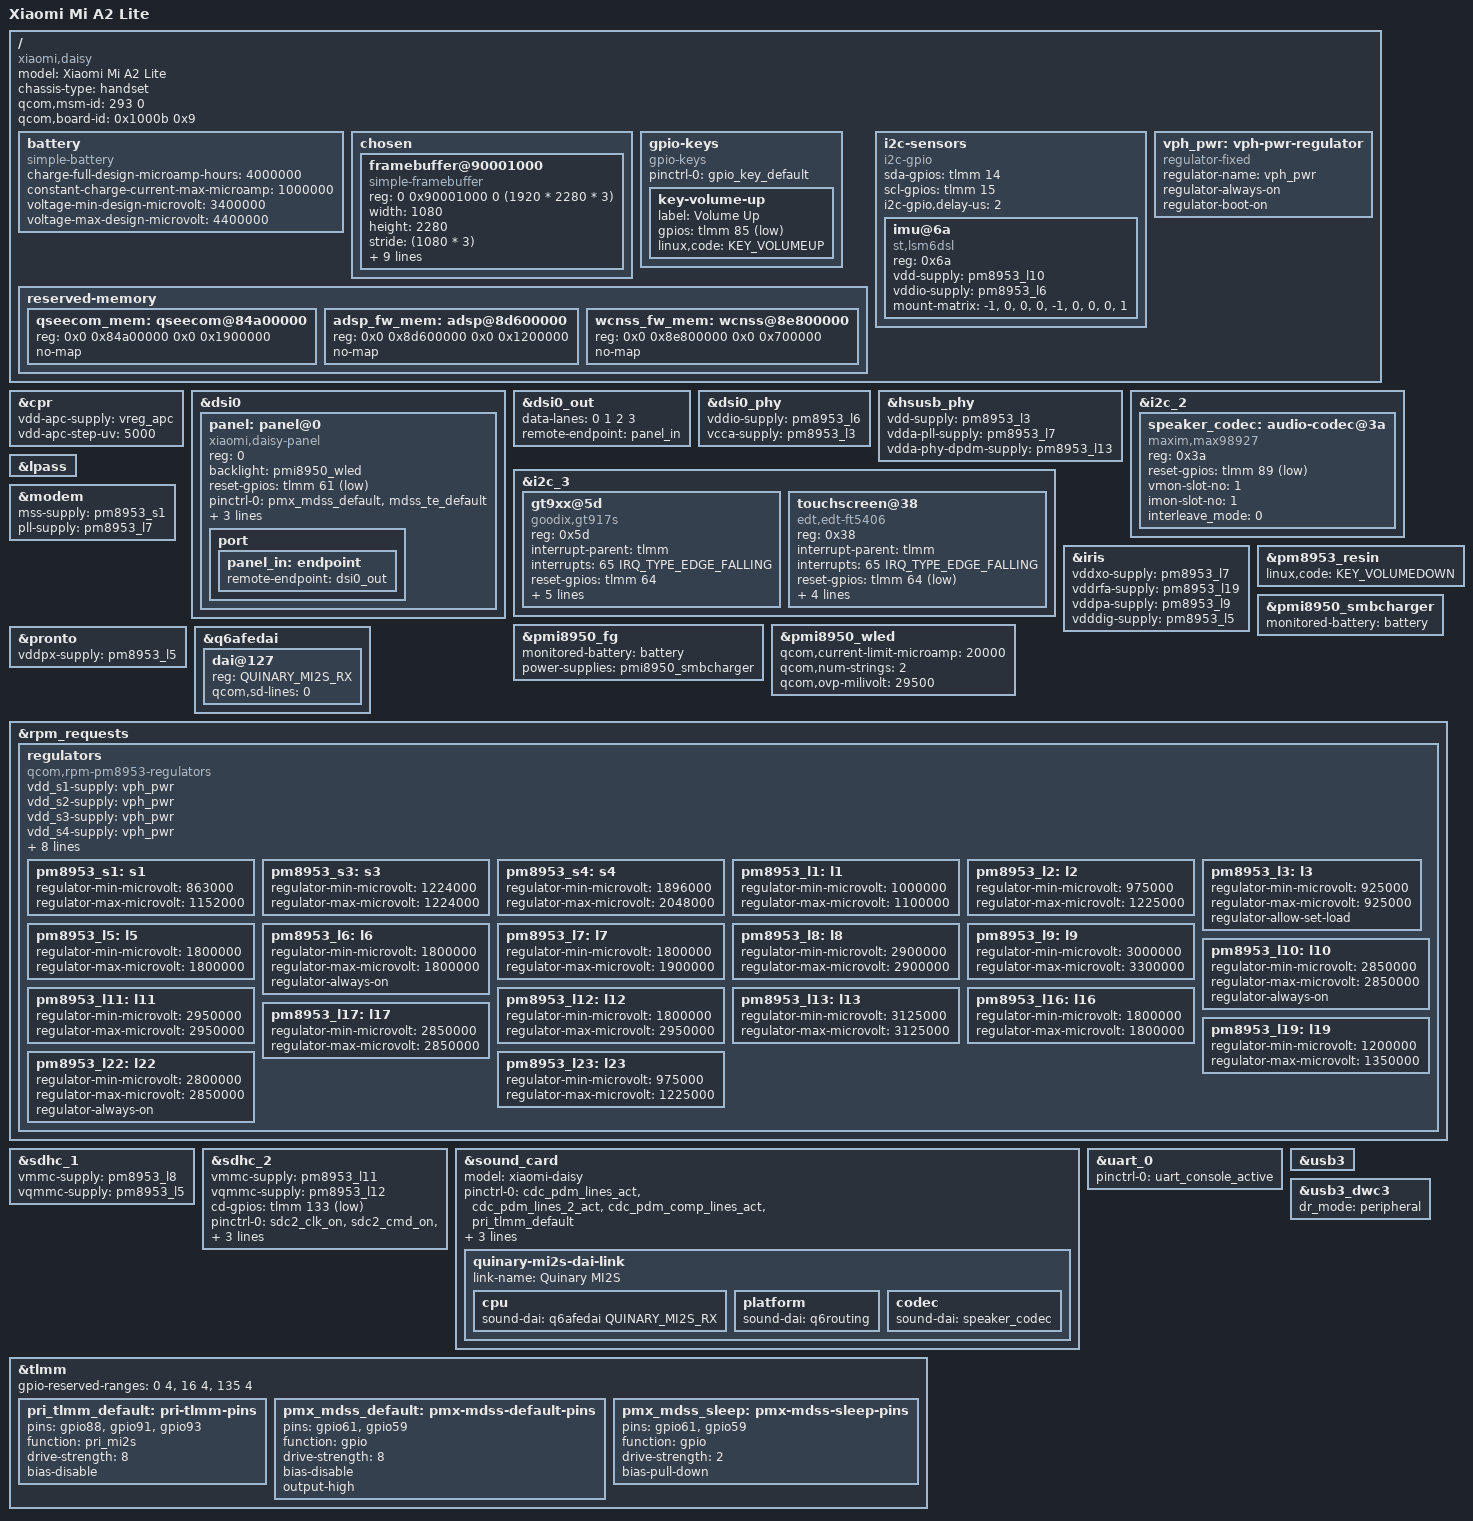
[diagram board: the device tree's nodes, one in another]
// SPDX-License-Identifier: BSD-3-Clause
/*
 * Copyright (c) 2022, Alejandro Tafalla
 */
/dts-v1/;

#include "msm8953.dtsi"
#include "pm8953.dtsi"
#include "pmi8950.dtsi"

#include <dt-bindings/gpio/gpio.h>
#include <dt-bindings/leds/common.h>

/delete-node/ &adsp_fw_mem;
/delete-node/ &qseecom_mem;
/delete-node/ &wcnss_fw_mem;

/ {
	model = "Xiaomi Mi A2 Lite";
	compatible = "xiaomi,daisy", "qcom,msm8953";
	chassis-type = "handset";
	qcom,msm-id = <293 0>;
	qcom,board-id= <0x1000b 0x9>;

	battery: battery {
		compatible = "simple-battery";
		charge-full-design-microamp-hours = <4000000>;
		constant-charge-current-max-microamp = <1000000>;
		voltage-min-design-microvolt = <3400000>;
		voltage-max-design-microvolt = <4400000>;
	};

	chosen {
		#address-cells = <2>;
		#size-cells = <2>;
		ranges;

		framebuffer@90001000 {
			compatible = "simple-framebuffer";
			reg = <0 0x90001000 0 (1920 * 2280 * 3)>;

			width = <1080>;
			height = <2280>;
			stride = <(1080 * 3)>;
			format = "r8g8b8";

			power-domains = <&gcc MDSS_GDSC>;

			clocks = <&gcc GCC_MDSS_AHB_CLK>,
				 <&gcc GCC_MDSS_AXI_CLK>,
				 <&gcc GCC_MDSS_VSYNC_CLK>,
				 <&gcc GCC_MDSS_MDP_CLK>,
				 <&gcc GCC_MDSS_BYTE0_CLK>,
				 <&gcc GCC_MDSS_PCLK0_CLK>,
				 <&gcc GCC_MDSS_ESC0_CLK>;
		};
	};

	gpio-keys {
		compatible = "gpio-keys";

		pinctrl-names = "default";
		pinctrl-0 = <&gpio_key_default>;

		key-volume-up {
			label = "Volume Up";
			gpios = <&tlmm 85 GPIO_ACTIVE_LOW>;
			linux,code = <KEY_VOLUMEUP>;
		};
	};

	reserved-memory {
		qseecom_mem: qseecom@84a00000 {
			reg = <0x0 0x84a00000 0x0 0x1900000>;
			no-map;
		};

		adsp_fw_mem: adsp@8d600000 {
			reg = <0x0 0x8d600000 0x0 0x1200000>;
			no-map;
		};

		wcnss_fw_mem: wcnss@8e800000 {
			reg = <0x0 0x8e800000 0x0 0x700000>;
			no-map;
		};
	};

	/*
	 * We bitbang on &i2c_4 because BLSP is protected by TZ as sensors are
	 * normally proxied via ADSP firmware. GPIOs aren't protected.
	 */
	i2c-sensors {
		compatible = "i2c-gpio";
		sda-gpios = <&tlmm 14 (GPIO_ACTIVE_HIGH|GPIO_OPEN_DRAIN)>;
		scl-gpios = <&tlmm 15 (GPIO_ACTIVE_HIGH|GPIO_OPEN_DRAIN)>;
		i2c-gpio,delay-us = <2>; /* ~100 kHz */
		#address-cells = <1>;
		#size-cells = <0>;

		imu@6a {
			compatible = "st,lsm6dsl";
			reg = <0x6a>;
			vdd-supply = <&pm8953_l10>;
			vddio-supply = <&pm8953_l6>;
			mount-matrix = "-1", "0", "0",
					"0", "-1", "0",
					"0", "0", "1";
		};
	};

	vph_pwr: vph-pwr-regulator {
		compatible = "regulator-fixed";
		regulator-name = "vph_pwr";
		regulator-always-on;
		regulator-boot-on;
	};
};

&cpr {
	vdd-apc-supply = <&vreg_apc>;
	vdd-apc-step-uv = <5000>;
};

&dsi0 {
	panel: panel@0 {
		compatible = "xiaomi,daisy-panel";
		reg = <0>;

		backlight = <&pmi8950_wled>;

		reset-gpios = <&tlmm 61 GPIO_ACTIVE_LOW>;

		pinctrl-names = "default", "sleep";
		pinctrl-0 = <&pmx_mdss_default &mdss_te_default>;
		pinctrl-1 = <&pmx_mdss_sleep &mdss_te_default>;

		vsp-supply = <&lab_vreg>;
		vsn-supply = <&ibb_vreg>;

		port {
			panel_in: endpoint {
				remote-endpoint = <&dsi0_out>;
			};
		};
	};
};

&dsi0_out {
	data-lanes = <0 1 2 3>;
	remote-endpoint = <&panel_in>;
};

&dsi0_phy {
        vddio-supply = <&pm8953_l6>;
        vcca-supply = <&pm8953_l3>;
};

&hsusb_phy {
	vdd-supply 		= <&pm8953_l3>;
	vdda-pll-supply 	= <&pm8953_l7>;
	vdda-phy-dpdm-supply 	= <&pm8953_l13>;

	status = "okay";
};

&i2c_2 {
	status = "okay";

	speaker_codec: audio-codec@3a {
		compatible = "maxim,max98927";
		reg = <0x3a>;

		reset-gpios = <&tlmm 89 GPIO_ACTIVE_LOW>;

		vmon-slot-no = <1>;
		imon-slot-no = <1>;
		interleave_mode = <0>;

		#sound-dai-cells = <0>;
	};
};

&i2c_3 {
	status = "okay";

	gt9xx@5d {
		compatible = "goodix,gt917s";
		reg = <0x5d>;

		interrupt-parent = <&tlmm>;
		interrupts = <65 IRQ_TYPE_EDGE_FALLING>;

		reset-gpios = <&tlmm 64 GPIO_ACTIVE_HIGH>;
		irq-gpios = <&tlmm 65 GPIO_ACTIVE_HIGH>;

		AVDD28-supply = <&pm8953_l10>;
		VDDIO-supply = <&pm8953_l6>;

		touchscreen-size-x = <1080>;
		touchscreen-size-y = <2280>;
	};

	touchscreen@38 {
		compatible = "edt,edt-ft5406", "edt,edt-ft5x06";
		reg = <0x38>;

		interrupt-parent = <&tlmm>;
		interrupts = <65 IRQ_TYPE_EDGE_FALLING>;

		reset-gpios = <&tlmm 64 GPIO_ACTIVE_LOW>;

		vcc-supply = <&pm8953_l10>;
		iovcc-supply = <&pm8953_l6>;

		touchscreen-size-x = <1080>;
		touchscreen-size-y = <2280>;
	};
};

&iris {
	vddxo-supply = <&pm8953_l7>;
	vddrfa-supply = <&pm8953_l19>;
	vddpa-supply = <&pm8953_l9>;
	vdddig-supply = <&pm8953_l5>;

	status = "okay";
};

&lpass {
	status = "okay";
};

&modem {
	status = "okay";

	mss-supply = <&pm8953_s1>;
	pll-supply = <&pm8953_l7>;
};


&pm8953_resin {
	linux,code = <KEY_VOLUMEDOWN>;
	status = "okay";
};

&pmi8950_fg {
	monitored-battery = <&battery>;
	power-supplies = <&pmi8950_smbcharger>;
	status = "okay";
};

&pmi8950_smbcharger {
	monitored-battery = <&battery>;
	status = "okay";
};

&pmi8950_wled {
	qcom,current-limit-microamp = <20000>;
	qcom,num-strings = <2>;
	qcom,ovp-milivolt = <29500>;

	status = "okay";
};

&pronto {
	vddpx-supply = <&pm8953_l5>;
	status = "okay";
};

&q6afedai {
	dai@127 {
		reg = <QUINARY_MI2S_RX>;
		qcom,sd-lines = <0>;
	};
};

&rpm_requests {
	regulators {
		compatible = "qcom,rpm-pm8953-regulators";

		vdd_s1-supply = <&vph_pwr>;
		vdd_s2-supply = <&vph_pwr>;
		vdd_s3-supply = <&vph_pwr>;
		vdd_s4-supply = <&vph_pwr>;
		vdd_s5-supply = <&vph_pwr>;
		vdd_s6-supply = <&vph_pwr>;
		vdd_s7-supply = <&vph_pwr>;
		vdd_l1-supply = <&pm8953_s3>;
		vdd_l2_l3-supply = <&pm8953_s3>;
		vdd_l4_l5_l6_l7_l16_l19-supply = <&pm8953_s4>;
		vdd_l8_l11_l12_l13_l14_l15-supply = <&vph_pwr>;
		vdd_l9_l10_l17_l18_l22-supply = <&vph_pwr>;

		pm8953_s1: s1 {
			regulator-min-microvolt = <863000>;
			regulator-max-microvolt = <1152000>;
		};

		pm8953_s3: s3 {
			regulator-min-microvolt = <1224000>;
			regulator-max-microvolt = <1224000>;
		};

		pm8953_s4: s4 {
			regulator-min-microvolt = <1896000>;
			regulator-max-microvolt = <2048000>;
		};

		pm8953_l1: l1 {
			regulator-min-microvolt = <1000000>;
			regulator-max-microvolt = <1100000>;
		};

		pm8953_l2: l2 {
			regulator-min-microvolt = <975000>;
			regulator-max-microvolt = <1225000>;
		};

		pm8953_l3: l3 {
			regulator-min-microvolt = <925000>;
			regulator-max-microvolt = <925000>;
			regulator-allow-set-load;
		};

		pm8953_l5: l5 {
			regulator-min-microvolt = <1800000>;
			regulator-max-microvolt = <1800000>;
		};

		pm8953_l6: l6 {
			regulator-min-microvolt = <1800000>;
			regulator-max-microvolt = <1800000>;
			regulator-always-on;
		};

		pm8953_l7: l7 {
			regulator-min-microvolt = <1800000>;
			regulator-max-microvolt = <1900000>;
		};

		pm8953_l8: l8 {
			regulator-min-microvolt = <2900000>;
			regulator-max-microvolt = <2900000>;
		};

		pm8953_l9: l9 {
			regulator-min-microvolt = <3000000>;
			regulator-max-microvolt = <3300000>;
		};

		pm8953_l10: l10 {
			regulator-min-microvolt = <2850000>;
			regulator-max-microvolt = <2850000>;
			regulator-always-on;
		};

		pm8953_l11: l11 {
			regulator-min-microvolt = <2950000>;
			regulator-max-microvolt = <2950000>;
		};

		pm8953_l12: l12 {
			regulator-min-microvolt = <1800000>;
			regulator-max-microvolt = <2950000>;
		};

		pm8953_l13: l13 {
			regulator-min-microvolt = <3125000>;
			regulator-max-microvolt = <3125000>;
		};

		pm8953_l16: l16 {
			regulator-min-microvolt = <1800000>;
			regulator-max-microvolt = <1800000>;
		};

		pm8953_l17: l17 {
			regulator-min-microvolt = <2850000>;
			regulator-max-microvolt = <2850000>;
		};

		pm8953_l19: l19 {
			regulator-min-microvolt = <1200000>;
			regulator-max-microvolt = <1350000>;
		};

		pm8953_l22: l22 {
			regulator-min-microvolt = <2800000>;
			regulator-max-microvolt = <2850000>;
			regulator-always-on;
		};

		pm8953_l23: l23 {
			regulator-min-microvolt = <975000>;
			regulator-max-microvolt = <1225000>;
		};
	};
};

&sdhc_1 {
	vmmc-supply = <&pm8953_l8>;
	vqmmc-supply = <&pm8953_l5>;

	status = "okay";
};

&sdhc_2 {
	vmmc-supply = <&pm8953_l11>;
	vqmmc-supply = <&pm8953_l12>;

	cd-gpios = <&tlmm 133 GPIO_ACTIVE_LOW>;

	pinctrl-names = "default", "sleep";
	pinctrl-0 = <&sdc2_clk_on &sdc2_cmd_on &sdc2_data_on &sdc2_cd_on>;
	pinctrl-1 = <&sdc2_clk_off &sdc2_cmd_off &sdc2_data_off &sdc2_cd_off>;

	status = "okay";
};

&sound_card {
	status = "okay";

	model = "xiaomi-daisy";

	pinctrl-names = "default", "sleep";
	pinctrl-0 = <&cdc_pdm_lines_act &cdc_pdm_lines_2_act &cdc_pdm_comp_lines_act &pri_tlmm_default>;
	pinctrl-1 = <&cdc_pdm_lines_sus &cdc_pdm_lines_2_sus &cdc_pdm_comp_lines_sus &pri_tlmm_default>;

	quinary-mi2s-dai-link {
		link-name = "Quinary MI2S";
		cpu {
			sound-dai = <&q6afedai QUINARY_MI2S_RX>;
		};

		platform {
			sound-dai = <&q6routing>;
		};

		codec {
			sound-dai = <&speaker_codec>;
		};
	};
};

&tlmm {
	gpio-reserved-ranges = <0 4>, <16 4>, <135 4>;

	pri_tlmm_default: pri-tlmm-pins {
		pins = "gpio88", "gpio91", "gpio93";
		function = "pri_mi2s";
		drive-strength = <8>;
		bias-disable;
	};

	pmx_mdss_default: pmx-mdss-default-pins {
		pins = "gpio61", "gpio59";
		function = "gpio";
		drive-strength = <8>;
		bias-disable;
		output-high;
	};

	pmx_mdss_sleep: pmx-mdss-sleep-pins {
		pins = "gpio61", "gpio59";
		function = "gpio";
		drive-strength = <2>;
		bias-pull-down;
	};
};

&uart_0 {
	pinctrl-names = "default";
	pinctrl-0 = <&uart_console_active>;

	status = "okay";
};

&usb3 {
	status = "okay";
};

&usb3_dwc3 {
	dr_mode = "peripheral";
};
